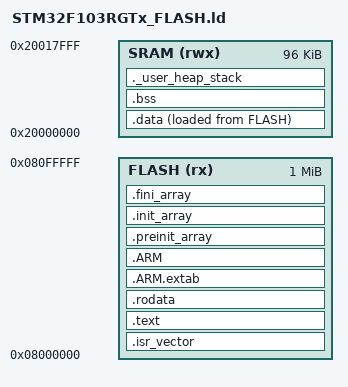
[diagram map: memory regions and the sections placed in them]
/*
 * STM32F103RGTx linker script for Keil MDK
 *
 * NOTE: Keil MDK uses its own scatter file format (.sct), not GNU LD scripts.
 * CubeMX generates the .sct file automatically. This .ld file is provided
 * for reference or if using GCC-based toolchains.
 *
 * Memory layout for STM32F103RGT6:
 *   Flash: 1MB  (0x08000000 - 0x080FFFFF)
 *   SRAM:  96KB (0x20000000 - 0x20017FFF)
 */

ENTRY(Reset_Handler)

MEMORY
{
    FLASH (rx)  : ORIGIN = 0x08000000, LENGTH = 1024K
    SRAM  (rwx) : ORIGIN = 0x20000000, LENGTH = 96K
}

SECTIONS
{
    .isr_vector :
    {
        . = ALIGN(4);
        KEEP(*(.isr_vector))
        . = ALIGN(4);
    } >FLASH

    .text :
    {
        . = ALIGN(4);
        *(.text)
        *(.text*)
        *(.glue_7)
        *(.glue_7t)
        *(.eh_frame)
        KEEP(*(.init))
        KEEP(*(.fini))
        . = ALIGN(4);
        _etext = .;
    } >FLASH

    .rodata :
    {
        . = ALIGN(4);
        *(.rodata)
        *(.rodata*)
        . = ALIGN(4);
    } >FLASH

    .ARM.extab :
    {
        *(.ARM.extab* .gnu.linkonce.armextab.*)
    } >FLASH

    .ARM :
    {
        __exidx_start = .;
        *(.ARM.exidx*)
        __exidx_end = .;
    } >FLASH

    .preinit_array :
    {
        PROVIDE_HIDDEN (__preinit_array_start = .);
        KEEP (*(.preinit_array*))
        PROVIDE_HIDDEN (__preinit_array_end = .);
    } >FLASH

    .init_array :
    {
        PROVIDE_HIDDEN (__init_array_start = .);
        KEEP (*(SORT(.init_array.*)))
        KEEP (*(.init_array*))
        PROVIDE_HIDDEN (__init_array_end = .);
    } >FLASH

    .fini_array :
    {
        PROVIDE_HIDDEN (__fini_array_start = .);
        KEEP (*(SORT(.fini_array.*)))
        KEEP (*(.fini_array*))
        PROVIDE_HIDDEN (__fini_array_end = .);
    } >FLASH

    _sidata = LOADADDR(.data);

    .data :
    {
        . = ALIGN(4);
        _sdata = .;
        *(.data)
        *(.data*)
        . = ALIGN(4);
        _edata = .;
    } >SRAM AT> FLASH

    .bss :
    {
        . = ALIGN(4);
        _sbss = .;
        __bss_start__ = _sbss;
        *(.bss)
        *(.bss*)
        *(COMMON)
        . = ALIGN(4);
        _ebss = .;
        __bss_end__ = _ebss;
    } >SRAM

    ._user_heap_stack :
    {
        . = ALIGN(8);
        PROVIDE (end = .);
        PROVIDE (_end = .);
        . = . + 0x400;
        . = ALIGN(8);
        . = . + 0x400;
    } >SRAM

    /DISCARD/ :
    {
        libc.a ( * )
        libm.a ( * )
        libgcc.a ( * )
    }
}
